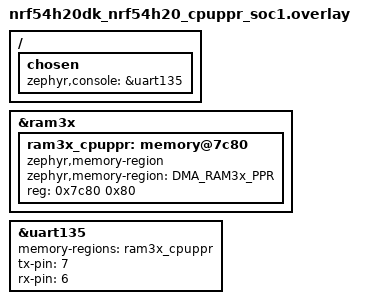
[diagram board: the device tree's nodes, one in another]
/*
 * Copyright (c) 2022 Nordic Semiconductor ASA
 *
 * SPDX-License-Identifier: LicenseRef-Nordic-5-Clause
 */

 / {
	chosen {
		zephyr,console = &uart135;
	};
};

&ram3x {
	ram3x_cpuppr: memory@7c80 {
		compatible = "zephyr,memory-region", "mmio-sram";
		zephyr,memory-region = "DMA_RAM3x_PPR";
		#memory-region-cells = < 0x0 >;
		reg = <0x7c80 0x80>;
	};
};

&uart135 {
	status = "okay";
	memory-regions = <&ram3x_cpuppr>;
	tx-pin = <7>;
	rx-pin = <6>;
};
